# STM32H5F5 register map
File version: 1.0
CPU: CM33 r0p0, little endian, MPU, FPU, 4 interrupt priority bits
Registers are 32-bit, read-write, reset 0x0 unless marked. A register's access mark holds for its fields unless they carry their own. Offsets are from the block's base; [hi:lo] are bit positions; {n}, {i} and the like mark numbered series; 'fields as' and 'values as' point back to an identical list.

## RAMCFG — RAMCFG register block
Base 0x40026000
Same registers: RAMCFG_S 0x50026000
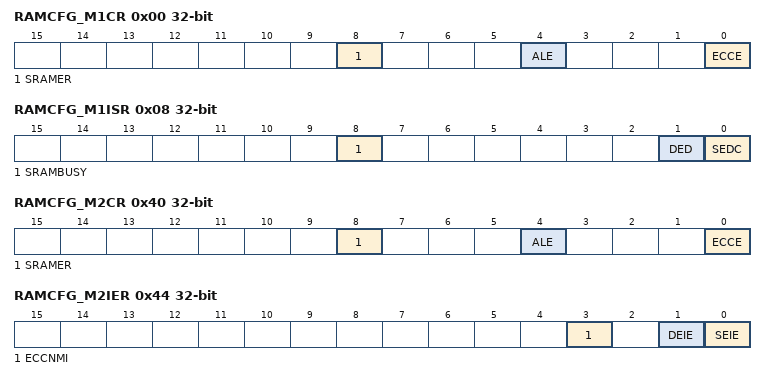
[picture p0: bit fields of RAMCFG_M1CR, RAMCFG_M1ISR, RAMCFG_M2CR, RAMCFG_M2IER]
0x00 RAMCFG_M1CR (reset mask 0xFFFFFFF0) — RAMCFG memory 1 control register
  [8] SRAMER — SRAM erase
    0=No erase operation ongoing; 1=Erase operation ongoing
  [4] ALE — Address latch enable
    0=Failing address not stored in the SRAMx ECC single/double error address registers; 1=Failing address stored in the SRAMx ECC single/double error address registers
  [0] ECCE — ECC enable.
    0=ECC disabled; 1=ECC enabled
0x08 RAMCFG_M1ISR ro — RAMCFG memory interrupt status register
  [8] SRAMBUSY — SRAM busy with erase operation
    0=No erase operation ongoing; 1=Erase operation ongoing
  [1] DED — ECC double error detected
    0=No double error; 1=Double error detected
  [0] SEDC — ECC single error detected and corrected
    0=No single error; 1=Single error detected and corrected
0x28 RAMCFG_M1ERKEYR wo — RAMCFG memory 1 erase key register
  [7:0] ERASEKEY — Erase write protection key
0x40 RAMCFG_M2CR (reset mask 0xFFFFFFF0) — RAMCFG memory 2 control register
  fields as RAMCFG_M1CR
0x44 RAMCFG_M2IER — RAMCFG memory 2 interrupt enable register
  [3] ECCNMI — Double error NMI
    0=NMI not generated in case of ECC double error; 1=NMI generated in case of ECC double error
  [1] DEIE — ECC double error interrupt enable
    0=Double error interrupt disabled; 1=Double error interrupt enabled
  [0] SEIE — ECC single error interrupt enable
    0=Single error interrupt disabled; 1=Single error interrupt enabled
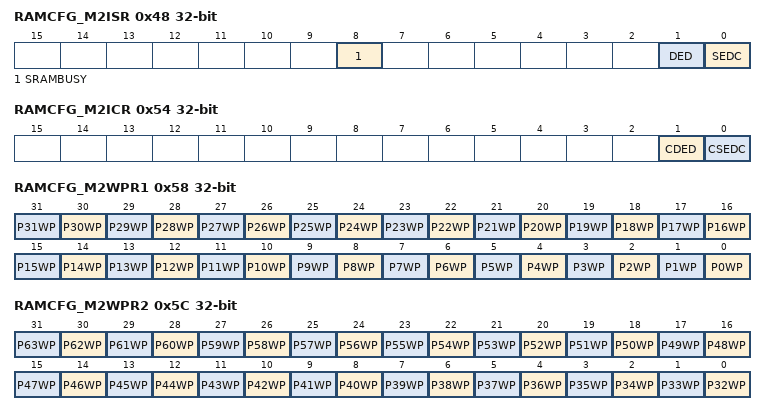
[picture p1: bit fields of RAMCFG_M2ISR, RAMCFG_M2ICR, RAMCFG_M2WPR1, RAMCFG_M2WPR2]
0x48 RAMCFG_M2ISR ro — RAMCFG memory interrupt status register
  fields as RAMCFG_M1ISR
0x4C RAMCFG_M2SEAR ro — RAMCFG memory 2 ECC single error address register
  [31:0] ESEA — ECC single error address
0x50 RAMCFG_M2DEAR ro — RAMCFG memory 2 ECC double error address register
  [31:0] EDEA — ECC double error address
0x54 RAMCFG_M2ICR — RAMCFG memory 2 interrupt clear register 2
  [1] CDED — Clear ECC double error detected
  [0] CSEDC — Clear ECC single error detected and corrected
0x58 RAMCFG_M2WPR1 — RAMCFG memory 2 write protection register 1
  [all] fields
    0=Write protection of SRAM2 1-Kbyte page y is disabled; 1=Write protection of SRAM2 1-Kbyte page y is enabled
  [n] P{n}WP (n=0..31) — SRAM2 1-Kbyte page y write protection
0x5C RAMCFG_M2WPR2 — RAMCFG memory 2 write protection register 2
  [all] fields
    values as the fields of RAMCFG_M2WPR1
  [n-32] P{n}WP (n=32..63) — SRAM2 1-Kbyte page y write protection
0x64 RAMCFG_M2ECCKEYR wo — RAMCFG memory 2 ECC key register
  [7:0] ECCKEY — ECC write protection key
0x68 RAMCFG_M2ERKEYR wo — RAMCFG memory 2 erase key register
  [7:0] ERASEKEY — Erase write protection key
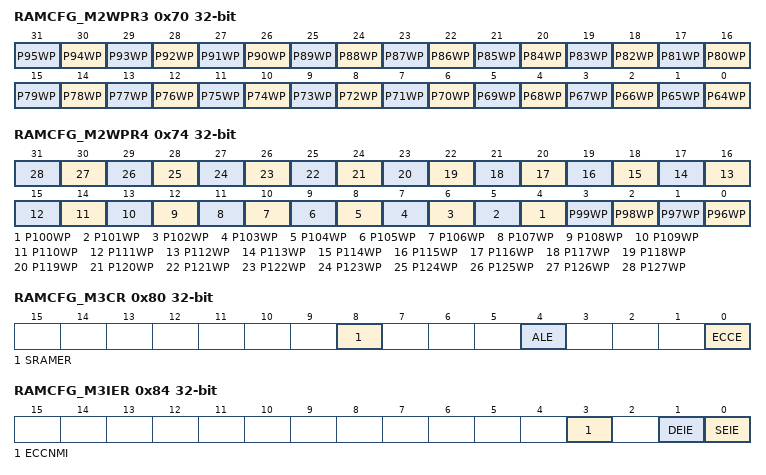
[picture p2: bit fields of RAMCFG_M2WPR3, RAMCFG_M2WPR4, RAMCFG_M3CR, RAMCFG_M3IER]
0x70 RAMCFG_M2WPR3 — RAMCFG memory 2 write protection register 3
  [all] fields
    values as the fields of RAMCFG_M2WPR1
  [n-64] P{n}WP (n=64..95) — SRAM2 1-Kbyte page y write protection
0x74 RAMCFG_M2WPR4 — RAMCFG memory 2 write protection register 4
  [all] fields
    values as the fields of RAMCFG_M2WPR1
  [n-96] P{n}WP (n=96..127) — SRAM2 1-Kbyte page y write protection
0x80 RAMCFG_M3CR (reset mask 0xFFFFFFF0) — RAMCFG memory 3 control register
  fields as RAMCFG_M1CR
0x84 RAMCFG_M3IER — RAMCFG memory 3 interrupt enable register
  fields as RAMCFG_M2IER
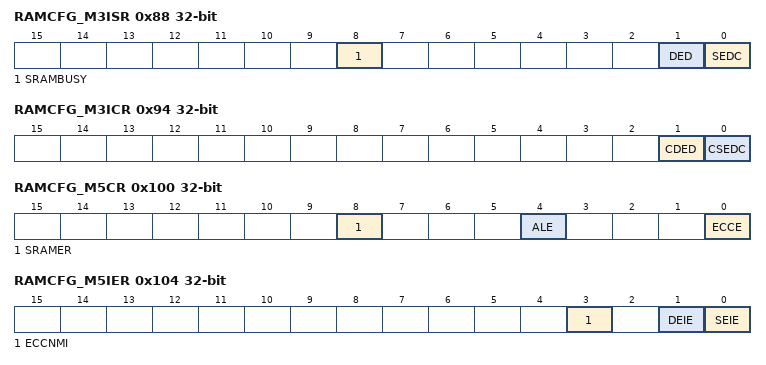
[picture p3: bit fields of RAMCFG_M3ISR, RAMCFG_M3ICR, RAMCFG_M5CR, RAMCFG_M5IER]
0x88 RAMCFG_M3ISR ro — RAMCFG memory interrupt status register
  fields as RAMCFG_M1ISR
0x8C RAMCFG_M3SEAR ro — RAMCFG memory 3 ECC single error address register
  [31:0] ESEA — ECC single error address
0x90 RAMCFG_M3DEAR ro — RAMCFG memory 3 ECC double error address register
  [31:0] EDEA — ECC double error address
0x94 RAMCFG_M3ICR — RAMCFG memory 3 interrupt clear register 3
  fields as RAMCFG_M2ICR
0xA4 RAMCFG_M3ECCKEYR wo — RAMCFG memory 3 ECC key register
  [7:0] ECCKEY — ECC write protection key
0xA8 RAMCFG_M3ERKEYR wo — RAMCFG memory 3 erase key register
  [7:0] ERASEKEY — Erase write protection key
0x100 RAMCFG_M5CR (reset mask 0xFFFFFFF0) — RAMCFG memory 5 control register
  fields as RAMCFG_M1CR
0x104 RAMCFG_M5IER — RAMCFG memory 5 interrupt enable register
  fields as RAMCFG_M2IER
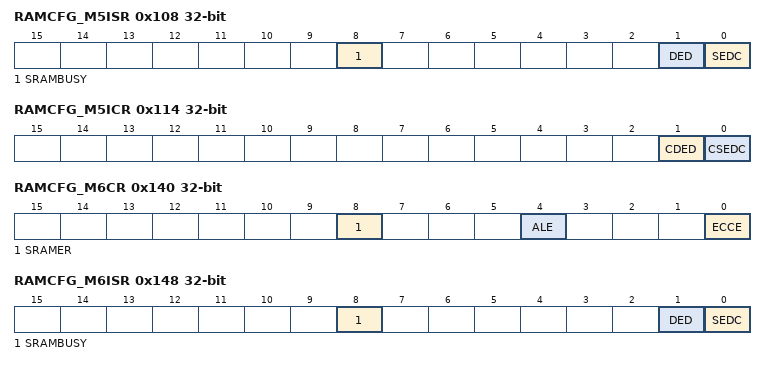
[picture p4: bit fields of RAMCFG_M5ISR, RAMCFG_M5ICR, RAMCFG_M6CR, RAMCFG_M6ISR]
0x108 RAMCFG_M5ISR ro — RAMCFG memory interrupt status register
  fields as RAMCFG_M1ISR
0x10C RAMCFG_M5SEAR ro — RAMCFG memory 5 ECC single error address register
  [31:0] ESEA — ECC single error address
0x110 RAMCFG_M5DEAR ro — RAMCFG memory 5 ECC double error address register
  [31:0] EDEA — ECC double error address
0x114 RAMCFG_M5ICR — RAMCFG memory 5 interrupt clear register 5
  fields as RAMCFG_M2ICR
0x124 RAMCFG_M5ECCKEYR wo — RAMCFG memory 5 ECC key register
  [7:0] ECCKEY — ECC write protection key
0x128 RAMCFG_M5ERKEYR wo — RAMCFG memory 5 erase key register
  [7:0] ERASEKEY — Erase write protection key
0x140 RAMCFG_M6CR (reset mask 0xFFFFFFF0) — RAMCFG memory 6 control register
  fields as RAMCFG_M1CR
0x148 RAMCFG_M6ISR ro — RAMCFG memory interrupt status register
  fields as RAMCFG_M1ISR
0x168 RAMCFG_M6ERKEYR wo — RAMCFG memory 6 erase key register
  [7:0] ERASEKEY — Erase write protection key
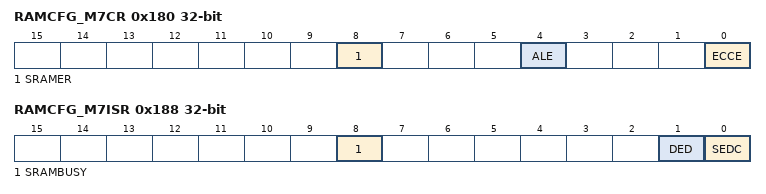
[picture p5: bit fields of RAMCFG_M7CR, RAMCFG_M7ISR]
0x180 RAMCFG_M7CR (reset mask 0xFFFFFFF0) — RAMCFG memory 7 control register
  fields as RAMCFG_M1CR
0x188 RAMCFG_M7ISR ro — RAMCFG memory interrupt status register
  fields as RAMCFG_M1ISR
0x1A8 RAMCFG_M7ERKEYR wo — RAMCFG memory 7 erase key register
  [7:0] ERASEKEY — Erase write protection key
